# ATSAMD20E16BU register map
Vendor: Microchip Technology Inc.; Series: SAMD20; File version: G
CPU: CM0+ r0p1, little endian, no MPU, no FPU, VTOR, 2 interrupt priority bits, 25 interrupts
Registers are 8-bit, read-write, reset 0x0 unless marked. A register's access mark holds for its fields unless they carry their own. Offsets are from the block's base; [hi:lo] are bit positions; 'fields as' and 'values as' point back to an identical list.

## SYSCTRL — System Control
Base 0x40000800; register names take the prefix SYSCTRL_
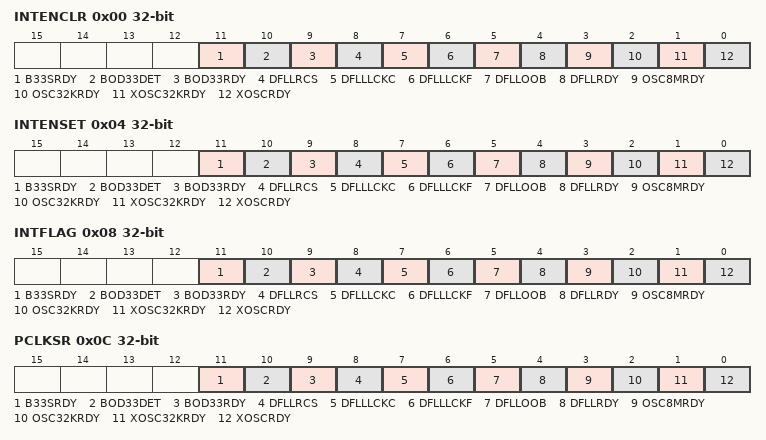
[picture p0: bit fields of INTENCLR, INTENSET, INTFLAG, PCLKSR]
0x00 INTENCLR 32-bit — Interrupt Enable Clear
  [11] B33SRDY — BOD33 Synchronization Ready
  [10] BOD33DET — BOD33 Detection
  [9] BOD33RDY — BOD33 Ready
  [8] DFLLRCS — DFLL Reference Clock Stopped
  [7] DFLLLCKC — DFLL Lock Coarse
  [6] DFLLLCKF — DFLL Lock Fine
  [5] DFLLOOB — DFLL Out Of Bounds
  [4] DFLLRDY — DFLL Ready
  [3] OSC8MRDY — OSC8M Ready
  [2] OSC32KRDY — OSC32K Ready
  [1] XOSC32KRDY — XOSC32K Ready
  [0] XOSCRDY — XOSC Ready
0x04 INTENSET 32-bit — Interrupt Enable Set
  fields as INTENCLR
0x08 INTFLAG 32-bit — Interrupt Flag Status and Clear
  fields as INTENCLR
0x0C PCLKSR 32-bit ro — Power and Clocks Status
  fields as INTENCLR
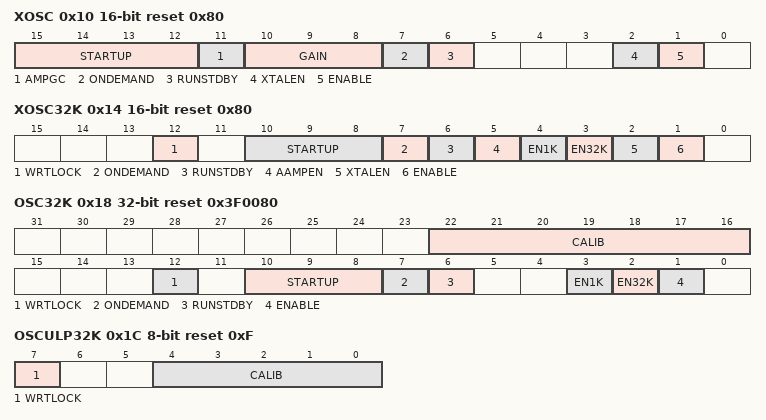
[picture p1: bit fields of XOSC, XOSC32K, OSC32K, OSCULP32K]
0x10 XOSC 16-bit reset 0x80 — XOSC Control
  [15:12] STARTUP — Start-Up Time
  [11] AMPGC — Automatic Amplitude Gain Control
  [10:8] GAIN — Gain Value
  [7] ONDEMAND — Enable on Demand
  [6] RUNSTDBY — Run during Standby
  [2] XTALEN — Crystal Oscillator Enable
  [1] ENABLE
0x14 XOSC32K 16-bit reset 0x80 — XOSC32K Control
  [12] WRTLOCK — Write Lock
  [10:8] STARTUP — Start-Up Time
  [7] ONDEMAND — Enable on Demand
  [6] RUNSTDBY — Run during Standby
  [5] AAMPEN — Automatic Amplitude Control Enable
  [4] EN1K — 1kHz Output Enable
  [3] EN32K — 32kHz Output Enable
  [2] XTALEN — Crystal Oscillator Enable
  [1] ENABLE
0x18 OSC32K 32-bit reset 0x3F0080 — OSC32K Control
  [22:16] CALIB — Calibration Value
  [12] WRTLOCK — Write Lock
  [10:8] STARTUP — Start-Up Time
  [7] ONDEMAND — Enable on Demand
  [6] RUNSTDBY — Run during Standby
  [3] EN1K — 1kHz Output Enable
  [2] EN32K — 32kHz Output Enable
  [1] ENABLE
0x1C OSCULP32K reset 0xF — OSCULP32K Control
  [7] WRTLOCK — Write Lock
  [4:0] CALIB — Calibration Value
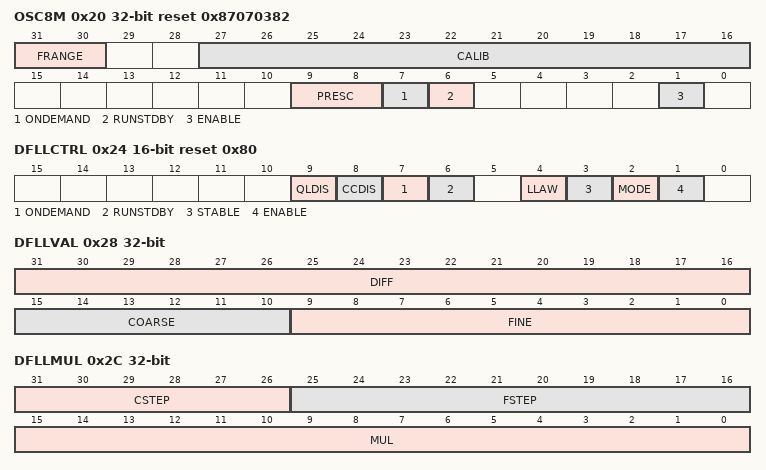
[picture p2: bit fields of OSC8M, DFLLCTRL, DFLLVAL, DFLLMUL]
0x20 OSC8M 32-bit reset 0x87070382 — OSC8M Control A
  [31:30] FRANGE — Frequency Range
  [27:16] CALIB — Calibration Value
  [9:8] PRESC — Prescaler Select
  [7] ONDEMAND — Enable on Demand
  [6] RUNSTDBY — Run during Standby
  [1] ENABLE
0x24 DFLLCTRL 16-bit reset 0x80 — DFLL Config
  [9] QLDIS — Quick Lock Disable
  [8] CCDIS — Chill Cycle Disable
  [7] ONDEMAND — Enable on Demand
  [6] RUNSTDBY — Run during Standby
  [4] LLAW — Lose Lock After Wake
  [3] STABLE — Stable Frequency
  [2] MODE — Mode Selection
  [1] ENABLE
0x28 DFLLVAL 32-bit — DFLL Calibration Value
  [31:16] DIFF ro — Multiplication Ratio Difference
  [15:10] COARSE — Coarse Calibration Value
  [9:0] FINE — Fine Calibration Value
0x2C DFLLMUL 32-bit — DFLL Multiplier
  [31:26] CSTEP — Maximum Coarse Step Size
  [25:16] FSTEP — Maximum Fine Step Size
  [15:0] MUL — Multiplication Value
0x30 DFLLSYNC — DFLL Synchronization
  [7] READREQ wo — Read Request Synchronization
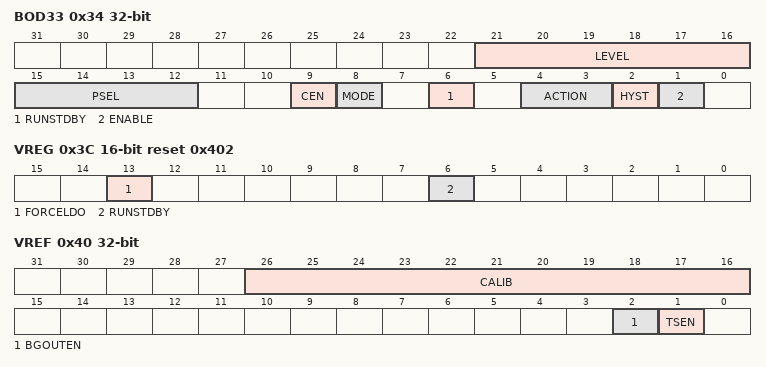
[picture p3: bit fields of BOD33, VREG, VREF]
0x34 BOD33 32-bit — 3.3V Brown-Out Detector (BOD33) Control
  [21:16] LEVEL — Threshold Level
  [15:12] PSEL — Prescaler Select
  [9] CEN — Clock Enable
  [8] MODE — Operation Modes
  [6] RUNSTDBY — Run during Standby
  [4:3] ACTION — Action when Threshold Crossed
  [2] HYST — Hysteresis Enable
  [1] ENABLE
0x3C VREG 16-bit reset 0x402 — VREG Control
  [13] FORCELDO — Force LDO Voltage Regulator
  [6] RUNSTDBY — Run during Standby
0x40 VREF 32-bit — VREF Control A
  [26:16] CALIB — Voltage Reference Calibration Value
  [2] BGOUTEN — Bandgap Output Enable
  [1] TSEN — Temperature Sensor Output Enable

## WDT — Watchdog Timer
Base 0x40001000; register names take the prefix WDT_
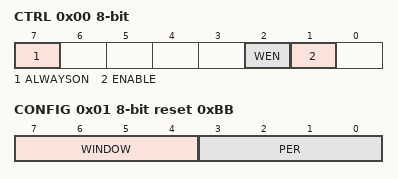
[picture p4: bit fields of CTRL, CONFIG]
0x00 CTRL — Control
  [7] ALWAYSON
  [2] WEN — Watchdog Timer Window Mode Enable
  [1] ENABLE
0x01 CONFIG reset 0xBB — Configuration
  [7:4] WINDOW — Window Mode Time-Out Period
    0=8 clock cycles; 1=16 clock cycles; 2=32 clock cycles; 3=64 clock cycles; 4=128 clock cycles; 5=256 clock cycles; 6=512 clock cycles; 7=1K (1024 clock cycles); 8=2K (2048 clock cycles); 9=4K (4096 clock cycles); 10=8K (8192 clock cycles); 11=16K (16384 clock cycles)
  [3:0] PER — Time-Out Period
    0=CYC8 (8 clock cycles); 1=CYC16 (16 clock cycles); 2=CYC32 (32 clock cycles); 3=CYC64 (64 clock cycles); 4=CYC128 (128 clock cycles); 5=CYC256 (256 clock cycles); 6=CYC512 (512 clock cycles); 7=CYC1024K (1024 clock cycles); 8=CYC2048 (2048 clock cycles); 9=CYC4096 (4096 clock cycles); 10=CYC8192 (8192 clock cycles); 11=CYC16384 (16384 clock cycles)
0x02 EWCTRL reset 0xB — Early Warning Interrupt Control
  [3:0] EWOFFSET — Early Warning Interrupt Time Offset
    0=CYC8 (8 clock cycles); 1=CYC16 (16 clock cycles); 2=CYC32 (32 clock cycles); 3=CYC64 (64 clock cycles); 4=CYC128 (128 clock cycles); 5=CYC256 (256 clock cycles); 6=CYC512 (512 clock cycles); 7=CYC1024 (1024 clock cycles); 8=CYC2048 (2048 clock cycles); 9=CYC4096 (4096 clock cycles); 10=CYC8192 (8192 clock cycles); 11=CYC16384 (16384 clock cycles)
0x04 INTENCLR — Interrupt Enable Clear
  [0] EW — Early Warning Interrupt Enable
0x05 INTENSET — Interrupt Enable Set
  [0] EW — Early Warning Interrupt Enable
0x06 INTFLAG — Interrupt Flag Status and Clear
  [0] EW — Early Warning
0x07 STATUS ro
  [7] SYNCBUSY — Synchronization Busy
0x08 CLEAR wo
  [7:0] CLEAR — Watchdog Clear
    165=KEY (Clear Key)

## Notices in the file
Copyright (c) 2020 Microchip Technology Inc.
SPDX-License-Identifier: Apache-2.0
Licensed under the Apache License, Version 2.0 (the "License");
you may not use this file except in compliance with the License.
You may obtain a copy of the License at
http://www.apache.org/licenses/LICENSE-2.0
Unless required by applicable law or agreed to in writing, software
distributed under the License is distributed on an "AS IS" BASIS,
WITHOUT WARRANTIES OR CONDITIONS OF ANY KIND, either express or implied.
See the License for the specific language governing permissions and
limitations under the License.
